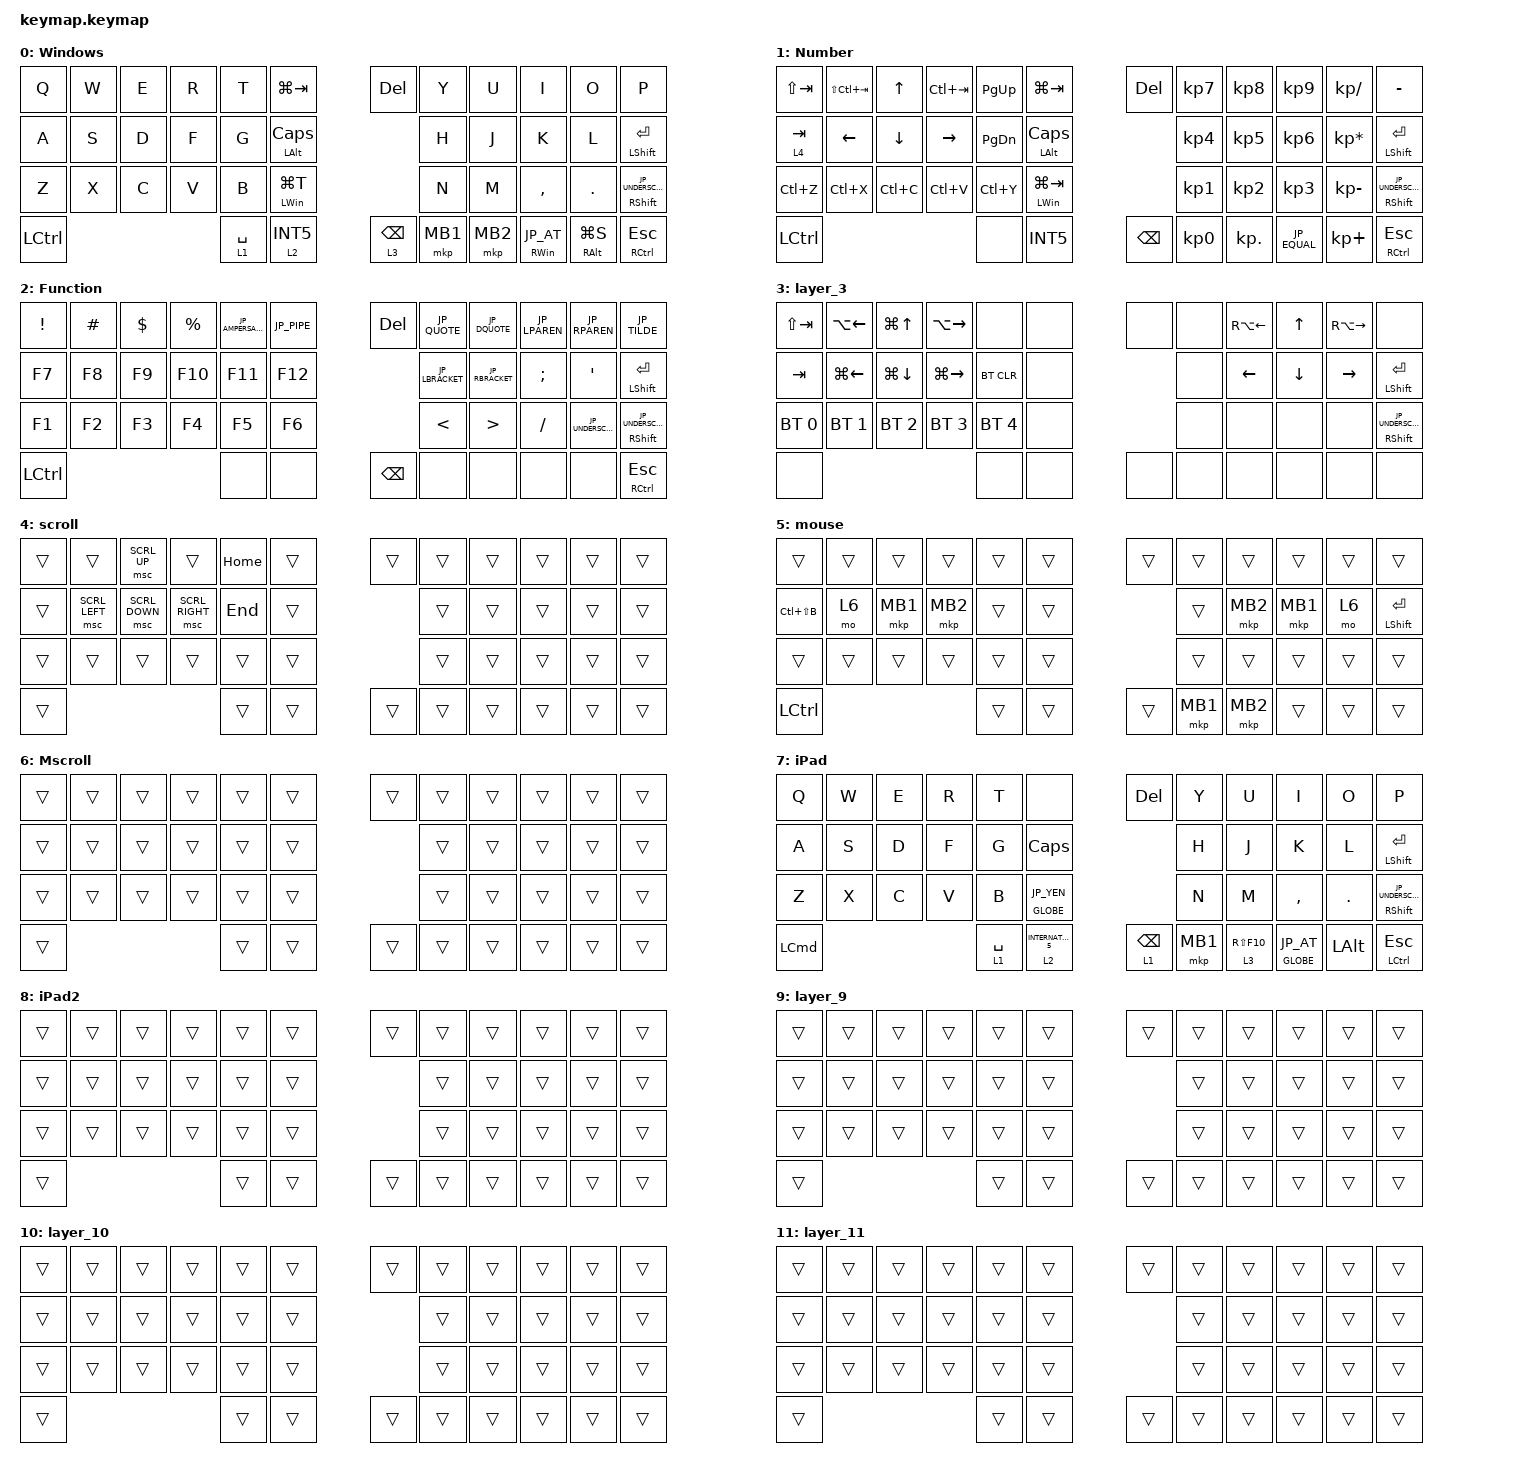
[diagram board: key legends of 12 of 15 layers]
#include <behaviors.dtsi>
#include <dt-bindings/zmk/bt.h>
#include <dt-bindings/zmk/keys.h>
#include <dt-bindings/zmk/pointing.h>

#define JP_DQUOTE       AT                // "
#define JP_AMPERSAND    CARET             // &
#define JP_QUOTE        AMPERSAND         // '
#define JP_EQUAL        UNDER             // =
#define JP_CARET        EQUAL             // ^
#define JP_YEN          0x89              // ¥
#define JP_PLUS         COLON             // +
#define JP_TILDE        PLUS              // ~
#define JP_PIPE         LS(0x89)          // |
#define JP_AT           LEFT_BRACKET      // @
#define JP_COLON        SINGLE_QUOTE      // :
#define JP_ASTERISK     DOUBLE_QUOTES     // *
#define JP_BACKQUOTE    LEFT_BRACE        // `
#define JP_UNDERSCORE   LS(0x87)          // _
#define JP_LBRACKET     RIGHT_BRACKET     // [
#define JP_RBRACKET     BACKSLASH         // ]
#define JP_LPAREN       ASTERISK          // (
#define JP_RPAREN       LEFT_PARENTHESIS  // )
#define JP_LBRACE       RIGHT_BRACE       // {
#define JP_RBRACE       PIPE              // }
#define JP_KANA         LANGUAGE_1        // かな
#define JP_EISU         LANGUAGE_2        // 英数
#define JP_HANZEN       GRAVE             // 半角/全角

/ {
    macros {
        bracket: bracket {
            compatible = "zmk,behavior-macro";
            #binding-cells = <0>;
            bindings = <&kp LBKT &kp RBKT &kp LEFT_ARROW>;
            label = "BRACKET";
        };

        thansign: thansign {
            compatible = "zmk,behavior-macro";
            #binding-cells = <0>;
            bindings = <&kp LT &kp GT &kp LEFT_ARROW>;
            label = "THANSIGN";
        };

        brace: brace {
            compatible = "zmk,behavior-macro";
            #binding-cells = <0>;
            bindings = <&kp LBRC &kp RBRC &kp LEFT_ARROW>;
            label = "BRACE";
        };

        paren: paren {
            compatible = "zmk,behavior-macro";
            #binding-cells = <0>;
            bindings = <&kp LPAR &kp RPAR &kp LEFT_ARROW>;
            label = "PAREN";
        };

        sel_win_0: sel_win_0 {
            compatible = "zmk,behavior-macro";
            #binding-cells = <0>;
            bindings = <&bt BT_SEL 0 &to 0>;
        };

        sel_win_1: sel_win_1 {
            compatible = "zmk,behavior-macro";
            #binding-cells = <0>;
            bindings = <&bt BT_SEL 1 &to 0>;
        };

        sel_win_2: sel_win_2 {
            compatible = "zmk,behavior-macro";
            #binding-cells = <0>;
            bindings = <&bt BT_SEL 2 &to 0>;
        };

        sel_ipad_3: sel_ipad_3 {
            compatible = "zmk,behavior-macro";
            #binding-cells = <0>;
            bindings = <&bt BT_SEL 3 &to 8>;
        };

        sel_ipad_4: sel_ipad_4 {
            compatible = "zmk,behavior-macro";
            #binding-cells = <0>;
            bindings = <&bt BT_SEL 4 &to 8>;
        }; //
    }; //
    behaviors {
        // タップでマウスボタン、長押しでレイヤー移動するカスタム設定

        lt_mouse: lt_mouse {
            compatible = "zmk,behavior-hold-tap";
            #binding-cells = <2>;
            flavor = "tap-preferred";    // タップ操作を優先する設定
            tapping-term-ms = <200>;     // 200ミリ秒以上の長押しでレイヤー切り替え
            bindings = <&mo>, <&mkp>;

            // 1つ目の引数にレイヤー(&mo)、2つ目にマウスボタン(&mkp)
        };
    };

    keymap {
        compatible = "zmk,keymap";

        Windows {
            bindings = <
&kp Q      &kp W  &kp E  &kp R  &kp T        &kp LG(TAB)            &kp DEL          &kp Y     &kp U     &kp I           &kp O           &kp P
&kp A      &kp S  &kp D  &kp F  &kp G        &mt LALT CAPS                           &kp H     &kp J     &kp K           &kp L           &mt LEFT_SHIFT ENTER
&kp Z      &kp X  &kp C  &kp V  &kp B        &mt LEFT_WIN LG(T)                      &kp N     &kp M     &kp COMMA       &kp PERIOD      &mt RIGHT_SHIFT JP_UNDERSCORE
&kp LCTRL                       &lt 1 SPACE  &lt 2 INT5             &lt 3 BACKSPACE  &mkp MB1  &mkp MB2  &mt RWIN JP_AT  &mt RALT LG(S)  &mt RCTRL ESC
            >;
        };

        Number {
            bindings = <
&kp LS(TAB)  &kp LS(LC(TAB))  &kp UP     &kp LC(TAB)    &kp PAGE_UP    &kp LG(TAB)         &kp DELETE     &kp KP_NUMBER_7  &kp KP_NUMBER_8  &kp KP_NUMBER_9  &kp KP_SLASH     &kp MINUS
&lt 4 TAB    &kp LEFT         &kp DOWN   &kp RIGHT      &kp PAGE_DOWN  &mt LALT CAPS                      &kp KP_NUMBER_4  &kp KP_NUMBER_5  &kp KP_NUMBER_6  &kp KP_MULTIPLY  &mt LEFT_SHIFT ENTER
&kp LC(Z)    &kp LC(X)        &kp LC(C)  &kp LC(V)      &kp LC(Y)      &mt LEFT_WIN LG(TAB)               &kp KP_NUMBER_1  &kp KP_NUMBER_2  &kp KP_NUMBER_3  &kp KP_MINUS     &mt RIGHT_SHIFT JP_UNDERSCORE
&kp LCTRL                                               &none          &kp INT5            &kp BACKSPACE  &kp KP_NUMBER_0  &kp KP_DOT       &kp JP_EQUAL     &kp KP_PLUS      &mt RCTRL ESC
            >;
        };

        Function {
            bindings = <
&kp EXCLAMATION  &kp HASH  &kp DOLLAR  &kp PERCENT  &kp JP_AMPERSAND  &kp JP_PIPE  &kp DEL        &kp JP_QUOTE     &kp JP_DQUOTE     &kp JP_LPAREN  &kp JP_RPAREN      &kp JP_TILDE
&kp F7           &kp F8    &kp F9      &kp F10      &kp F11           &kp F12                     &kp JP_LBRACKET  &kp JP_RBRACKET   &kp SEMICOLON  &kp SINGLE_QUOTE   &mt LEFT_SHIFT ENTER
&kp F1           &kp F2    &kp F3      &kp F4       &kp F5            &kp F6                      &kp LESS_THAN    &kp GREATER_THAN  &kp SLASH      &kp JP_UNDERSCORE  &mt RIGHT_SHIFT JP_UNDERSCORE
&kp LCTRL                                           &none             &none        &kp BACKSPACE  &none            &none             &none          &none              &mt RCTRL ESC
            >;
        };

        layer_3 {
            bindings = <
&kp LS(TAB)   &kp LA(LEFT)  &kp LG(UP)    &kp LA(RIGHT)  &none         &none  &none  &none  &kp RA(LEFT_ARROW)  &kp UP    &kp RA(RIGHT_ARROW)  &none
&kp TAB       &kp LG(LEFT)  &kp LG(DOWN)  &kp LG(RIGHT)  &bt BT_CLR    &none         &none  &kp LEFT            &kp DOWN  &kp RIGHT            &mt LEFT_SHIFT ENTER
&bt BT_SEL 0  &bt BT_SEL 1  &bt BT_SEL 2  &bt BT_SEL 3   &bt BT_SEL 4  &none         &none  &none               &none     &none                &mt RIGHT_SHIFT JP_UNDERSCORE
&none                                                    &none         &none  &none  &none  &none               &none     &none                &none
            >;
        };

        scroll {
            bindings = <
&trans  &trans          &msc SCRL_UP    &trans           &kp HOME  &trans  &trans  &trans  &trans  &trans  &trans  &trans
&trans  &msc SCRL_LEFT  &msc SCRL_DOWN  &msc SCRL_RIGHT  &kp END   &trans          &trans  &trans  &trans  &trans  &trans
&trans  &trans          &trans          &trans           &trans    &trans          &trans  &trans  &trans  &trans  &trans
&trans                                                   &trans    &trans  &trans  &trans  &trans  &trans  &trans  &trans
            >;
        };

        mouse {
            bindings = <
&trans         &trans  &trans    &trans    &trans  &trans  &trans  &trans    &trans    &trans    &trans  &trans
&kp LC(LS(B))  &mo 6   &mkp MB1  &mkp MB2  &trans  &trans          &trans    &mkp MB2  &mkp MB1  &mo 6   &mt LEFT_SHIFT ENTER
&trans         &trans  &trans    &trans    &trans  &trans          &trans    &trans    &trans    &trans  &trans 
&kp LCTRL                                  &trans  &trans  &trans  &mkp MB1  &mkp MB2  &trans    &trans  &trans
            >;
        };

        Mscroll {
            bindings = <
&trans  &trans  &trans  &trans  &trans  &trans  &trans  &trans  &trans  &trans  &trans  &trans
&trans  &trans  &trans  &trans  &trans  &trans          &trans  &trans  &trans  &trans  &trans
&trans  &trans  &trans  &trans  &trans  &trans          &trans  &trans  &trans  &trans  &trans
&trans                          &trans  &trans  &trans  &trans  &trans  &trans  &trans  &trans
            >;
        };

        iPad {
            bindings = <
&kp Q             &kp W  &kp E  &kp R  &kp T        &none                  &kp DELETE       &kp Y     &kp U          &kp I            &kp O         &kp P
&kp A             &kp S  &kp D  &kp F  &kp G        &kp CAPSLOCK                            &kp H     &kp J          &kp K            &kp L         &mt LEFT_SHIFT ENTER
&kp Z             &kp X  &kp C  &kp V  &kp B        &mt GLOBE JP_YEN                        &kp N     &kp M          &kp COMMA        &kp DOT       &mt RIGHT_SHIFT JP_UNDERSCORE
&kp LEFT_COMMAND                       &lt 1 SPACE  &lt 2 INTERNATIONAL_5  &lt 1 BACKSPACE  &mkp MB1  &lt 3 RS(F10)  &mt GLOBE JP_AT  &kp LEFT_ALT  &mt LCTRL ESC
            >;
        };

        iPad2 {
            bindings = <
&trans  &trans  &trans  &trans  &trans  &trans  &trans  &trans  &trans  &trans  &trans  &trans
&trans  &trans  &trans  &trans  &trans  &trans          &trans  &trans  &trans  &trans  &trans
&trans  &trans  &trans  &trans  &trans  &trans          &trans  &trans  &trans  &trans  &trans
&trans                          &trans  &trans  &trans  &trans  &trans  &trans  &trans  &trans
            >;
        };

        layer_9 {
            bindings = <
&trans  &trans  &trans  &trans  &trans  &trans  &trans  &trans  &trans  &trans  &trans  &trans
&trans  &trans  &trans  &trans  &trans  &trans          &trans  &trans  &trans  &trans  &trans
&trans  &trans  &trans  &trans  &trans  &trans          &trans  &trans  &trans  &trans  &trans
&trans                          &trans  &trans  &trans  &trans  &trans  &trans  &trans  &trans
            >;
        };

        layer_10 {
            bindings = <
&trans  &trans  &trans  &trans  &trans  &trans  &trans  &trans  &trans  &trans  &trans  &trans
&trans  &trans  &trans  &trans  &trans  &trans          &trans  &trans  &trans  &trans  &trans
&trans  &trans  &trans  &trans  &trans  &trans          &trans  &trans  &trans  &trans  &trans
&trans                          &trans  &trans  &trans  &trans  &trans  &trans  &trans  &trans
            >;
        };

        layer_11 {
            bindings = <
&trans  &trans  &trans  &trans  &trans  &trans  &trans  &trans  &trans  &trans  &trans  &trans
&trans  &trans  &trans  &trans  &trans  &trans          &trans  &trans  &trans  &trans  &trans
&trans  &trans  &trans  &trans  &trans  &trans          &trans  &trans  &trans  &trans  &trans
&trans                          &trans  &trans  &trans  &trans  &trans  &trans  &trans  &trans
            >;
        };

        layer_12 {
            bindings = <
&trans  &trans  &trans  &trans  &trans  &trans  &trans  &trans  &trans  &trans  &trans  &trans
&trans  &trans  &trans  &trans  &trans  &trans          &trans  &trans  &trans  &trans  &trans
&trans  &trans  &trans  &trans  &trans  &trans          &trans  &trans  &trans  &trans  &trans
&trans                          &trans  &trans  &trans  &trans  &trans  &trans  &trans  &trans
            >;
        };

        layer_13 {
            bindings = <
&trans  &trans  &trans  &trans  &trans  &trans  &trans  &trans  &trans  &trans  &trans  &trans
&trans  &trans  &trans  &trans  &trans  &trans          &trans  &trans  &trans  &trans  &trans
&trans  &trans  &trans  &trans  &trans  &trans          &trans  &trans  &trans  &trans  &trans
&trans                          &trans  &trans  &trans  &trans  &trans  &trans  &trans  &trans
            >;
        };

        layer_14 {
            bindings = <
&trans  &trans  &trans  &trans  &trans  &trans  &trans  &trans  &trans  &trans  &trans  &trans
&trans  &trans  &trans  &trans  &trans  &trans          &trans  &trans  &trans  &trans  &trans
&trans  &trans  &trans  &trans  &trans  &trans          &trans  &trans  &trans  &trans  &trans
&trans                          &trans  &trans  &trans  &trans  &trans  &trans  &trans  &trans
            >;
        };
    };
};
